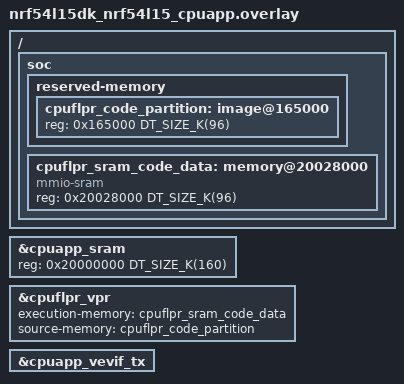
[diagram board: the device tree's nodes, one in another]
/*
 * Copyright (c) 2025 Nordic Semiconductor ASA
 *
 * SPDX-License-Identifier: LicenseRef-Nordic-5-Clause
 */

#include "app_aliases_common.dtsi"

/* The following configuration is required to run the CPUFLPR core.
 * It is imported from the nordic-flpr snippet in the sdk-zephyr repository.
 */
/ {
	soc {
		reserved-memory {
			#address-cells = <1>;
			#size-cells = <1>;

			cpuflpr_code_partition: image@165000 {
				/* FLPR core code partition */
				reg = <0x165000 DT_SIZE_K(96)>;
			};
		};

		cpuflpr_sram_code_data: memory@20028000 {
			compatible = "mmio-sram";
			reg = <0x20028000 DT_SIZE_K(96)>;
			#address-cells = <1>;
			#size-cells = <1>;
			ranges = <0x0 0x20028000 0x18000>;
		};
	};
};

&cpuapp_sram {
	reg = <0x20000000 DT_SIZE_K(160)>;
	ranges = <0x0 0x20000000 0x28000>;
};

&cpuflpr_vpr {
	status = "okay";
	execution-memory = <&cpuflpr_sram_code_data>;
	source-memory = <&cpuflpr_code_partition>;
};

&cpuapp_vevif_tx {
	status = "okay";
};

/* The same set of GPIO and GPIOTE DTS nodes are enabled in the cpuapp and the cpuflpr targets.
 * This is done to allow control over one Button and one LED in each core. The benchmark code is
 * responsible for ensuring that each core exclusively uses the individual GPIO pin and the GPIOTE
 * instance that may be used with the GPIO pin (Button).
 */
